# K32L2B21A register map
Vendor: NXP Semiconductors; Series: Kinetis; File version: 1.6
CPU: CM0PLUS r0p0, little endian, no MPU, no FPU, VTOR, 2 interrupt priority bits
Registers are 32-bit, read-write, reset 0x0 unless marked. A register's access mark holds for its fields unless they carry their own. Offsets are from the block's base; [hi:lo] are bit positions; {n}, {i} and the like mark numbered series; 'fields as' and 'values as' point back to an identical list.

## MCG — Multipurpose Clock Generator Lite
Base 0x40064000; register names take the prefix MCG_
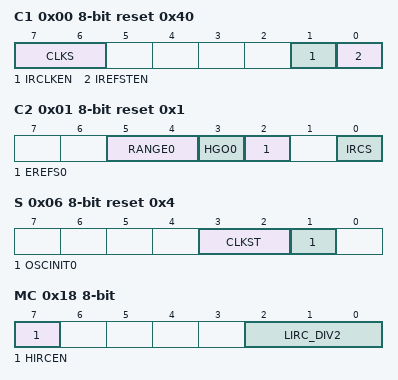
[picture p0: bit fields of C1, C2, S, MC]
0x00 C1 8-bit reset 0x40 — MCG Control Register 1
  [7:6] CLKS — Clock Source Select
    0=Selects HIRC clock as the main clock source. This is HIRC mode.; 1=Selects LIRC clock as the main clock source. This is LIRC2M or LIRC8M mode.; 2=Selects external clock as the main clock source. This is EXT mode.; 3=Reserved. Writing 11 takes no effect.
  [1] IRCLKEN — Internal Reference Clock Enable
    0=LIRC is disabled; 1=LIRC is enabled
  [0] IREFSTEN — Internal Reference Stop Enable
    0=LIRC is disabled in Stop mode; 1=LIRC is enabled in Stop mode, if IRCLKEN is set
0x01 C2 8-bit reset 0x1 — MCG Control Register 2
  [5:4] RANGE0 — External Clock Source Frequency Range Select
    0=Low frequency range selected for the crystal oscillator or the external clock source; 1=High frequency range selected for the crystal oscillator or the external clock source; 2=Very high frequency range selected for the crystal oscillator or the external clock source; 3=Very high frequency range selected for the crystal oscillator or the external clock source. Same effect as 10.
  [3] HGO0 — Crystal Oscillator Operation Mode Select
    0=Configure crystal oscillator for low-power operation; 1=Configure crystal oscillator for high-gain operation
  [2] EREFS0 — External Clock Source Select
    0=External clock requested; 1=Oscillator requested
  [0] IRCS — Low-frequency Internal Reference Clock Select
    0=LIRC is in 2 MHz mode; 1=LIRC is in 8 MHz mode
0x06 S 8-bit ro reset 0x4 — MCG Status Register
  [3:2] CLKST — Clock Mode Status
    0=HIRC clock is selected as the main clock source, and MCG_Lite works at HIRC mode; 1=LIRC clock is selected as the main clock source, and MCG_Lite works at LIRC2M or LIRC8M mode; 2=External clock is selected as the main clock source, and MCG_Lite works at EXT mode
  [1] OSCINIT0 — OSC Initialization Status
    0=OSC is not ready; 1=OSC clock is ready
0x08 SC 8-bit — MCG Status and Control Register
  [3:1] FCRDIV — Low-frequency Internal Reference Clock Divider
    0=Division factor is 1; 1=Division factor is 2; 2=Division factor is 4; 3=Division factor is 8; 4=Division factor is 16; 5=Division factor is 32; 6=Division factor is 64; 7=Division factor is 128
0x18 MC 8-bit — MCG Miscellaneous Control Register
  [7] HIRCEN — High-frequency IRC Enable
    0=HIRC source is not enabled; 1=HIRC source is enabled
  [2:0] LIRC_DIV2 — Second Low-frequency Internal Reference Clock Divider
    values as SC.FCRDIV

## OSC0 — Oscillator
Base 0x40065000; register names take the prefix OSC0_
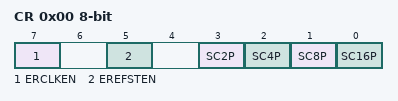
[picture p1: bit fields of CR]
0x00 CR 8-bit — OSC Control Register
  [7] ERCLKEN — External Reference Enable
    0=External reference clock is inactive; 1=External reference clock is enabled
  [5] EREFSTEN — External Reference Stop Enable
    0=External reference clock is disabled in Stop mode; 1=External reference clock stays enabled in Stop mode if ERCLKEN is set before entering Stop mode
  [3] SC2P — Oscillator 2 pF Capacitor Load Configure
    0=Disable the selection; 1=Add 2 pF capacitor to the oscillator load
  [2] SC4P — Oscillator 4 pF Capacitor Load Configure
    0=Disable the selection; 1=Add 4 pF capacitor to the oscillator load
  [1] SC8P — Oscillator 8 pF Capacitor Load Configure
    0=Disable the selection; 1=Add 8 pF capacitor to the oscillator load
  [0] SC16P — Oscillator 16 pF Capacitor Load Configure
    0=Disable the selection; 1=Add 16 pF capacitor to the oscillator load

## CMP0 — High-Speed Comparator (CMP), Voltage Reference (VREF) Digital-to-Analog Converter (DAC), and Analog Mux (ANMUX)
Base 0x40073000; register names take the prefix CMP0_
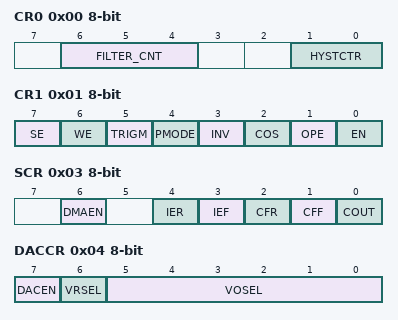
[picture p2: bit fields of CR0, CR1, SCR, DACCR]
0x00 CR0 8-bit — CMP Control Register 0
  [6:4] FILTER_CNT — Filter Sample Count
    0=Filter is disabled. SE = 0, COUT = COUTA.; 1=One sample must agree. The comparator output is simply sampled.; {v}={v} consecutive samples must agree (v=2..7)
  [1:0] HYSTCTR — Comparator hard block hysteresis control
    {v}=Level {v} (v=0..3)
0x01 CR1 8-bit — CMP Control Register 1
  [7] SE — Sample Enable
    0=Sampling mode is not selected; 1=Sampling mode is selected
  [6] WE — Windowing Enable
    0=Windowing mode is not selected; 1=Windowing mode is selected
  [5] TRIGM — Trigger Mode Enable
    0=Trigger mode is disabled; 1=Trigger mode is enabled
  [4] PMODE — Power Mode Select
    0=Low-Speed (LS) Comparison mode selected. In this mode, CMP has slower output propagation delay and lower current consumption.; 1=High-Speed (HS) Comparison mode selected. In this mode, CMP has faster output propagation delay and higher current consumption.
  [3] INV — Comparator INVERT
    0=Does not invert the comparator output; 1=Inverts the comparator output
  [2] COS — Comparator Output Select
    0=Set the filtered comparator output (CMPO) to equal COUT; 1=Set the unfiltered comparator output (CMPO) to equal COUTA
  [1] OPE — Comparator Output Pin Enable
    0=CMPO is not available on the associated CMPO output pin. If the comparator does not own the pin, this field has no effect.; 1=CMPO is available on the associated CMPO output pin. The comparator output (CMPO) is driven out on the associated CMPO output pin if the comparator owns the pin. If the comparator does not own the field, this bit has no effect.
  [0] EN — Comparator Module Enable
    0=Analog Comparator is disabled; 1=Analog Comparator is enabled
0x02 FPR 8-bit — CMP Filter Period Register
  [7:0] FILT_PER — Filter Sample Period
0x03 SCR 8-bit — CMP Status and Control Register
  [6] DMAEN — DMA Enable Control
    0=DMA is disabled; 1=DMA is enabled
  [4] IER — Comparator Interrupt Enable Rising
    0=Interrupt is disabled; 1=Interrupt is enabled
  [3] IEF — Comparator Interrupt Enable Falling
    0=Interrupt is disabled; 1=Interrupt is enabled
  [2] CFR — Analog Comparator Flag Rising
    0=Rising-edge on COUT has not been detected; 1=Rising-edge on COUT has occurred
  [1] CFF — Analog Comparator Flag Falling
    0=Falling-edge on COUT has not been detected; 1=Falling-edge on COUT has occurred
  [0] COUT ro — Analog Comparator Output
0x04 DACCR 8-bit — DAC Control Register
  [7] DACEN — DAC Enable
    0=DAC is disabled; 1=DAC is enabled
  [6] VRSEL — Supply Voltage Reference Source Select
    0=Vin1 is selected as resistor ladder network supply reference; 1=Vin2 is selected as resistor ladder network supply reference
  [5:0] VOSEL — DAC Output Voltage Select
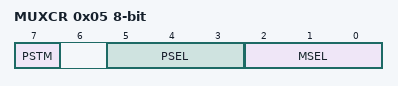
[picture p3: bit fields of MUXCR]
0x05 MUXCR 8-bit — MUX Control Register
  [7] PSTM — Pass Through Mode Enable
    0=Pass Through Mode is disabled; 1=Pass Through Mode is enabled
  [5:3] PSEL — Plus Input Mux Control
    {v}=IN{v} (v=0..7)
  [2:0] MSEL — Minus Input Mux Control
    {v}=IN{v} (v=0..7)
